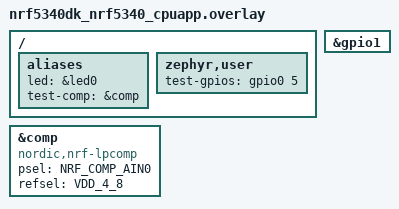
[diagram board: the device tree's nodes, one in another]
/*
 * Copyright (c) 2025 Nordic Semiconductor ASA
 *
 * SPDX-License-Identifier: LicenseRef-Nordic-5-Clause
 */

#include <zephyr/dt-bindings/comparator/nrf-comp.h>

/ {
	aliases {
		led = &led0;
		test-comp = &comp;
	};

	zephyr,user {
		test-gpios = <&gpio0 5 GPIO_ACTIVE_HIGH>;
	};
};

&gpio1 {
	status = "okay";
};

&comp {
	compatible = "nordic,nrf-lpcomp";
	psel = <NRF_COMP_AIN0>; /* P0.04 */
	refsel = "VDD_4_8";
	status = "okay";
};
